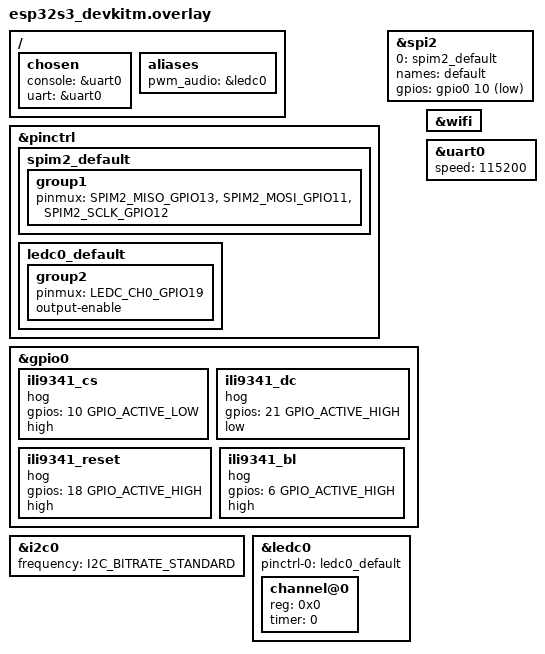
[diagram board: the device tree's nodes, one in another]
// Include required headers
#include <zephyr/dt-bindings/gpio/gpio.h>
#include <zephyr/dt-bindings/spi/spi.h>

// Configure SPI pins - Fixed pin mapping
&pinctrl
{
spim2_default:
    spim2_default
    {
        group1
        {
            pinmux = <SPIM2_MISO_GPIO13>, // MISO - GPIO13
                <SPIM2_MOSI_GPIO11>,      // MOSI - GPIO11
                <SPIM2_SCLK_GPIO12>;      // SCK  - GPIO12
        };
    };
};

&spi2
{
    status = "okay";
    pinctrl - 0 = <&spim2_default>;
    pinctrl - names = "default";
    cs - gpios = <&gpio0 10 GPIO_ACTIVE_LOW>; // Manual CS control
};

&gpio0
{
    status = "okay";
// ILI9341 Display Control Pins
ili9341_cs:
    ili9341_cs
    {
        gpio - hog;
        gpios = <10 GPIO_ACTIVE_LOW>; // CS - GPIO10
        output - high;                // CS idle high
    };

ili9341_dc:
    ili9341_dc
    {
        gpio - hog;
        gpios = <21 GPIO_ACTIVE_HIGH>; // DC - GPIO21
        output - low;                  // DC starts low (command mode)
    };

ili9341_reset:
    ili9341_reset
    {
        gpio - hog;
        gpios = <18 GPIO_ACTIVE_HIGH>; // RESET - GPIO18
        output - high;                 // RESET idle high
    };

ili9341_bl:
    ili9341_bl
    {
        gpio - hog;
        gpios = <6 GPIO_ACTIVE_HIGH>; // Backlight - GPIO6
        output - high;                // Backlight on
    };
};

// WiFi configuration
&wifi
{
    status = "okay";
    // WiFi credentbgials will be managed by settings module
};

// UART configuration for shell and logging
&uart0
{
    status = "okay";
    current - speed = <115200>;
};

// I2C configuration (for future expansion)
&i2c0
{
    status = "okay";
    clock - frequency = <I2C_BITRATE_STANDARD>;
    // Reserved for future peripherals:
    // - IMU/Accelerometer
    // - Audio codec
    // - Battery management IC
};

// PWM configuration for audio output (LEDC peripheral)
&ledc0
{
    status = "okay";
    pinctrl-0 = <&ledc0_default>;
    pinctrl-names = "default";
    #address-cells = <1>;
    #size-cells = <0>;
    
    // Channel 0 for audio output
    channel@0
    {
        reg = <0x0>;
        timer = <0>;
    };
};

&pinctrl
{
    ledc0_default: ledc0_default
    {
        group2
        {
            pinmux = <LEDC_CH0_GPIO19>; // Audio output on GPIO19
            output-enable;
        };
    };
};

// Chosen nodes for Zephyr configuration
/
{
    chosen
    {
        zephyr, console = &uart0;
        zephyr, shell - uart = &uart0;
    };
    
    aliases
    {
        pwm_audio = &ledc0;
    };
};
